# STM32L4P5 register map
File version: 1.8
CPU: CM4 r0p1, little endian, MPU, FPU, 4 interrupt priority bits
Registers are 32-bit, read-write, reset 0x0 unless marked. A register's access mark holds for its fields unless they carry their own. Offsets are from the block's base; [hi:lo] are bit positions; {n}, {i} and the like mark numbered series; 'fields as' and 'values as' point back to an identical list.

## RCC — Reset and clock control
Base 0x40021000
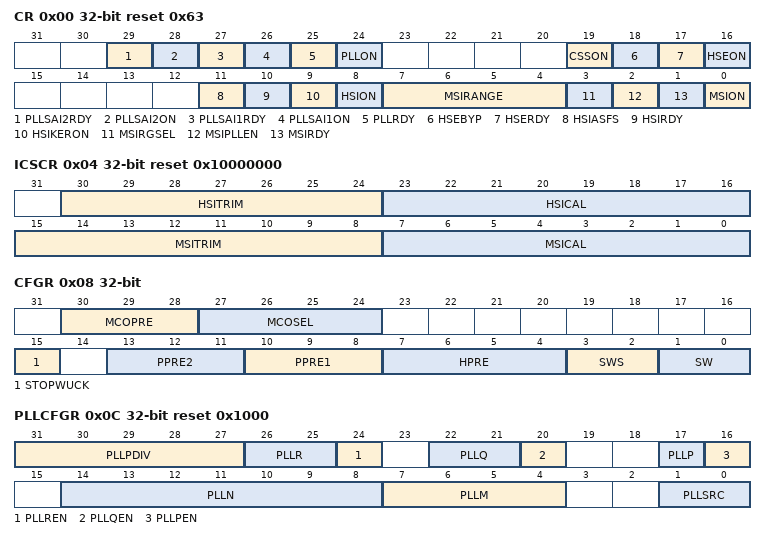
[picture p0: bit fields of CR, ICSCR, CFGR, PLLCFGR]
0x00 CR access per field reset 0x63 — Clock control register
  [29] PLLSAI2RDY ro — SAI2 PLL clock ready flag
    0=Unlocked (PLLSAI2 unlocked); 1=Locked (PLLSAI2 locked)
  [28] PLLSAI2ON rw — SAI2 PLL enable
    0=Disabled (PLLSAI2 OFF); 1=Enabled (PLLSAI2 ON)
  [27] PLLSAI1RDY ro — SAI1 PLL clock ready flag
    0=Unlocked (PLLSAI1 unlocked); 1=Locked (PLLSAI1 locked)
  [26] PLLSAI1ON rw — SAI1 PLL enable
    0=Disabled (PLLSAI1 OFF); 1=Enabled (PLLSAI1 ON)
  [25] PLLRDY ro — Main PLL clock ready flag
    0=Unlocked (PLL unlocked); 1=Locked (PLL locked)
  [24] PLLON rw — Main PLL enable
    0=Disabled (PLL OFF); 1=Enabled (PLL ON)
  [19] CSSON wo — Clock security system enable
    0=Disabled (Clock security system OFF (clock detector OFF)); 1=Enabled (Clock security system ON (Clock detector ON if the HSE oscillator is stable, OFF if not))
  [18] HSEBYP rw — HSE crystal oscillator bypass
    0=NotBypassed (HSE crystal oscillator not bypassed); 1=Bypassed (HSE crystal oscillator bypassed with external clock)
  [17] HSERDY ro — HSE clock ready flag
    0=NotReady (HSE oscillator not ready); 1=Ready (HSE oscillator ready)
  [16] HSEON rw — HSE clock enable
    0=Disabled (HSE oscillator OFF); 1=Enabled (HSE oscillator ON)
  [11] HSIASFS rw — HSI automatic start from Stop
    0=Disabled (HSI16 oscillator is not enabled by hardware when exiting Stop mode with MSI as wakeup clock); 1=Enabled (HSI16 oscillator is enabled by hardware when exiting Stop mode with MSI as wakeup clock)
  [10] HSIRDY ro — HSI clock ready flag
    0=NotReady (HSI16 oscillator not ready); 1=Ready (HSI16 oscillator ready)
  [9] HSIKERON rw — HSI always enable for peripheral kernels
    0=Disabled (No effect on HSI16 oscillator); 1=Enabled (HSI16 oscillator is forced ON even in Stop mode)
  [8] HSION rw — HSI clock enable
    0=Disabled (HSI16 oscillator OFF); 1=Enabled (HSI16 oscillator ON)
  [7:4] MSIRANGE rw — MSI clock ranges
    0=Range100K (range 0 around 100 kHz); 1=Range200K (range 1 around 200 kHz); 2=Range400K (range 2 around 400 kHz); 3=Range800K (range 3 around 800 kHz); 4=Range1M (range 4 around 1 MHz); 5=Range2M (range 5 around 2 MHz); 6=Range4M (range 6 around 4 MHz); 7=Range8M (range 7 around 8 MHz); 8=Range16M (range 8 around 16 MHz); 9=Range24M (range 9 around 24 MHz); 10=Range32M (range 10 around 32 MHz); 11=Range48M (range 11 around 48 MHz)
  [3] MSIRGSEL wo — MSI clock range selection
    0=CSR (MSI Range is provided by MSISRANGE[3:0] in RCC_CSR register); 1=CR (MSI Range is provided by MSIRANGE[3:0] in the RCC_CR register)
  [2] MSIPLLEN rw — MSI clock PLL enable
    0=Disabled (MSI PLL OFF); 1=Enabled (MSI PLL ON)
  [1] MSIRDY ro — MSI clock ready flag
    0=NotReady (MSI oscillator not ready); 1=Ready (MSI oscillator ready)
  [0] MSION rw — MSI clock enable
    0=Disabled (MSI oscillator OFF); 1=Enabled (MSI oscillator ON)
0x04 ICSCR access per field reset 0x10000000 — Internal clock sources calibration register
  [30:24] HSITRIM rw — HSI clock trimming
  [23:16] HSICAL ro — HSI clock calibration
  [15:8] MSITRIM rw — MSI clock trimming
  [7:0] MSICAL ro — MSI clock calibration
0x08 CFGR access per field — Clock configuration register
  [30:28] MCOPRE ro — Microcontroller clock output prescaler
    0=Divider1 (MCO is divided by 1); 1=Divider2 (MCO is divided by 2); 2=Divider4 (MCO is divided by 4); 3=Divider8 (MCO is divided by 8); 4=Divider16 (MCO is divided by 16)
  [27:24] MCOSEL rw — Microcontroller clock output
    0=Disabled (MCO output disabled, no clock on MCO); 1=SYSCLK (SYSCLK system clock selected); 2=MSI (MSI clock selected.); 3=HSI16 (HSI16 clock selected.); 4=HSE (HSE clock selected); 5=Main PLL clock selected; 6=LSI (LSI clock selected); 7=LSE (LSE clock selected); 8=HSI48 (Internal HSI48 clock selected)
  [15] STOPWUCK rw — Wakeup from Stop and CSS backup clock selection
    0=MSI (MSI oscillator selected as wakeup from stop clock and CSS backup clock); 1=HSI16 (HSI16 oscillator selected as wakeup from stop clock and CSS backup clock)
  [13:11] PPRE2 rw — APB high-speed prescaler (APB2)
    4=Div2 (HCLK divided by 2); 5=Div4 (HCLK divided by 4); 6=Div8 (HCLK divided by 8); 7=Div16 (HCLK divided by 16); other=Div1 (HCLK not divided)
  [10:8] PPRE1 rw — PB low-speed prescaler (APB1)
    values as PPRE2
  [7:4] HPRE rw — AHB prescaler
    8=Div2 (SYSCLK divided by 2); 9=Div4 (SYSCLK divided by 4); 10=Div8 (SYSCLK divided by 8); 11=Div16 (SYSCLK divided by 16); 12=Div64 (SYSCLK divided by 64); 13=Div128 (SYSCLK divided by 128); 14=Div256 (SYSCLK divided by 256); 15=Div512 (SYSCLK divided by 512); other=Div1 (SYSCLK not divided)
  [3:2] SWS ro — System clock switch status
    0=MSI (MSI oscillator used as system clock); 1=HSI16 (HSI16 oscillator used as system clock); 2=HSE (HSE used as system clock); 3=PLL (PLL used as system clock)
  [1:0] SW rw — System clock switch
    0=MSI (MSI selected as system clock); 1=HSI16 (HSI16 selected as system clock); 2=HSE (HSE selected as system clock); 3=PLL (PLL selected as system clock)
0x0C PLLCFGR reset 0x1000 — PLL configuration register
  [31:27] PLLPDIV — Main PLL division factor for PLLSAI2CLK
    0=PLLP (PLLSAI3CLK is controlled by the bit PLLP); {v}=Div{v} (PLLSAI3CLK = VCO / {v}) (v=2..31)
  [26:25] PLLR — Main PLL division factor for PLLCLK (system clock)
    0=Div2 (PLLx = 2); 1=Div4 (PLLx = 4); 2=Div6 (PLLx = 6); 3=Div8 (PLLx = 8)
  [24] PLLREN — Main PLL PLLCLK output enable
    0=Disabled (PLLCLK output disable); 1=Enabled (PLLCLK output enabled)
  [22:21] PLLQ — Main PLL division factor for PLLUSB1CLK(48 MHz clock)
    values as PLLR
  [20] PLLQEN — Main PLL PLLUSB1CLK output enable
    0=Disabled (PLL48M1CLK output disable); 1=Enabled (PLL48M1CLK output enabled)
  [17] PLLP — Main PLL division factor for PLLSAI3CLK (SAI1 and SAI2 clock)
    0=Div7 (PLLP = 7); 1=Div17 (PLLP = 17)
  [16] PLLPEN — Main PLL PLLSAI3CLK output enable
    0=Disabled (PLLSAI3CLK output disable); 1=Enabled (PLLSAI3CLK output enabled)
  [14:8] PLLN range 8..127 — Main PLL multiplication factor for VCO
  [7:4] PLLM — Division factor for the main PLL and audio PLL (PLLSAI1 and PLLSAI2) input clock
    {v}=Div{v+1} (PLLM = {v+1}) (v=0..8); 9=Div10 (PLLM = 11); 10=Div11 (PLLM = 12); 11=Div12 (PLLM = 13); {v}=Div{v+1} (PLLM = {v+1}) (v=12..15)
  [1:0] PLLSRC — Main PLL, PLLSAI1 and PLLSAI2 entry clock source
    0=No clock sent to PLL; 1=MSI (MSI clock selected as PLL clock entry); 2=HSI16 (HSI16 clock selected as PLL clock entry); 3=HSE (HSE clock selected as PLL clock entry)
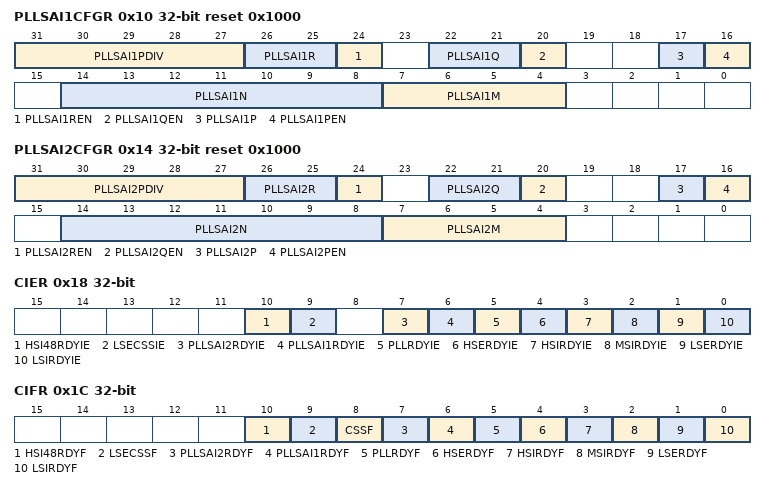
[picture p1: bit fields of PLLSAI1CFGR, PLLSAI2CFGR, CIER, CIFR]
0x10 PLLSAI1CFGR reset 0x1000 — PLLSAI1 configuration register
  [31:27] PLLSAI1PDIV — PLLSAI1 division factor for PLLSAI1CLK
    0=PLLSAI1P (PLLSAI1CLK is controlled by the bit PLLSAI1P); {v}=Div{v} (PLLSAI1CLK = VCOSAI / {v}) (v=2..31)
  [26:25] PLLSAI1R — PLLSAI1 division factor for PLLADC1CLK (ADC clock)
    0=Div2 (PLLSAI1x = 2); 1=Div4 (PLLSAI1x = 4); 2=Div6 (PLLSAI1x = 6); 3=Div8 (PLLSAI1x = 8)
  [24] PLLSAI1REN — PLLSAI1 PLLADC1CLK output enable
    0=Disabled (PLLADC1CLK output disable); 1=Enabled (PLLADC1CLK output enabled)
  [22:21] PLLSAI1Q — SAI1PLL division factor for PLLUSB2CLK (48 MHz clock)
    values as PLLSAI1R
  [20] PLLSAI1QEN — SAI1PLL PLLUSB2CLK output enable
    0=Disabled (PLL48M2CLK output disable); 1=Enabled (PLL48M2CLK output enabled)
  [17] PLLSAI1P — SAI1PLL division factor for PLLSAI1CLK (SAI1 or SAI2 clock)
    0=Div7 (PLLSAI1P = 7); 1=Div17 (PLLSAI1P = 17)
  [16] PLLSAI1PEN — SAI1PLL PLLSAI1CLK output enable
    0=Disabled (PLLSAI1CLK output disable); 1=Enabled (PLLSAI1CLK output enabled)
  [14:8] PLLSAI1N range 8..127 — SAI1PLL multiplication factor for VCO
  [7:4] PLLSAI1M — Division factor for PLLSAI1 input clock
    {v}=Div{v+1} (PLLSAI1M = {v+1}) (v=0..8); 9=Div10 (PLLSAI1M = 11); 10=Div11 (PLLSAI1M = 12); 11=Div12 (PLLSAI1M = 13); {v}=Div{v+1} (PLLSAI1M = {v+1}) (v=12..15)
0x14 PLLSAI2CFGR reset 0x1000 — PLLSAI2 configuration register
  [31:27] PLLSAI2PDIV — PLLSAI2 division factor for PLLSAI2CLK
    0=PLLSAI1P (PLLSAI2CLK is controlled by the bit PLLSAI2P); {v}=Div{v} (PLLSAI2CLK = VCOSAI2 / {v}) (v=2..31)
  [26:25] PLLSAI2R — PLLSAI2 division factor for PLLADC2CLK (ADC clock)
    0=Div2 (PLLSAI2x = 2); 1=Div4 (PLLSAI2x = 4); 2=Div6 (PLLSAI2x = 6); 3=Div8 (PLLSAI2x = 8)
  [24] PLLSAI2REN — PLLSAI2 PLLADC2CLK output enable
    0=Disabled (PLLLCDCLK output disable); 1=Enabled (PLLLCDCLK output enabled)
  [22:21] PLLSAI2Q — SAI2PLL PLLSAI2CLK output enable
    values as PLLSAI2R
  [20] PLLSAI2QEN — PLLSAI2 division factor for PLLDISCLK
    0=Disabled (PLLDSICLK output disable); 1=Enabled (PLLDSICLK output enabled)
  [17] PLLSAI2P — SAI1PLL division factor for PLLSAI2CLK (SAI1 or SAI2 clock)
    0=Div7 (PLLSAI2P = 7); 1=Div17 (PLLSAI2P = 17)
  [16] PLLSAI2PEN — SAI2PLL PLLSAI2CLK output enable
    0=Disabled (PLLSAI2CLK output disable); 1=Enabled (PLLSAI2CLK output enabled)
  [14:8] PLLSAI2N range 8..127 — SAI2PLL multiplication factor for VCO
  [7:4] PLLSAI2M — Division factor for PLLSAI2 input clock
    {v}=Div{v+1} (PLLSAI2M = {v+1}) (v=0..8); 9=Div10 (PLLSAI2M = 11); 10=Div11 (PLLSAI2M = 12); 11=Div12 (PLLSAI2M = 13); {v}=Div{v+1} (PLLSAI2M = {v+1}) (v=12..15)
0x18 CIER — Clock interrupt enable register
  [10] HSI48RDYIE — HSI48 ready interrupt enable
    0=Disabled (HSI48 ready interrupt disabled); 1=Enabled (HSI48 ready interrupt enabled)
  [9] LSECSSIE — LSE clock security system interrupt enable
    0=Disabled (Clock security interrupt caused by LSE clock failure disabled); 1=Enabled (Clock security interrupt caused by LSE clock failure enabled)
  [7] PLLSAI2RDYIE — PLLSAI2 ready interrupt enable
    0=Disabled (PLLSAI2 lock interrupt disabled); 1=Enabled (PLLSAI2 lock interrupt enabled)
  [6] PLLSAI1RDYIE — PLLSAI1 ready interrupt enable
    0=Disabled (PLLSAI1 lock interrupt disabled); 1=Enabled (PLLSAI1 lock interrupt enabled)
  [5] PLLRDYIE — PLL ready interrupt enable
    0=Disabled (PLL lock interrupt disabled); 1=Enabled (PLL lock interrupt enabled)
  [4] HSERDYIE — HSE ready interrupt enable
    0=Disabled (HSE ready interrupt disabled); 1=Enabled (HSE ready interrupt enabled)
  [3] HSIRDYIE — HSI ready interrupt enable
    0=Disabled (HSI16 ready interrupt disabled); 1=Enabled (HSI16 ready interrupt enabled)
  [2] MSIRDYIE — MSI ready interrupt enable
    0=Disabled (MSI ready interrupt disabled); 1=Enabled (MSI ready interrupt enabled)
  [1] LSERDYIE — LSE ready interrupt enable
    0=Disabled (LSE ready interrupt disabled); 1=Enabled (LSE ready interrupt enabled)
  [0] LSIRDYIE — LSI ready interrupt enable
    0=Disabled (LSI ready interrupt disabled); 1=Enabled (LSI ready interrupt enabled)
0x1C CIFR ro — Clock interrupt flag register
  [10] HSI48RDYF — HSI48 ready interrupt flag
    0=NoInterrupt (No clock ready interrupt caused by the HSI48 oscillator); 1=Interrupt (Clock ready interrupt caused by the HSI48 oscillator)
  [9] LSECSSF — LSE Clock security system interrupt flag
    0=NoInterrupt (No clock security interrupt caused by LSE clock failure); 1=Interrupt (Clock security interrupt caused by LSE clock failure)
  [8] CSSF — Clock security system interrupt flag
    0=NoInterrupt (No clock security interrupt caused by HSE clock failure); 1=Interrupt (Clock security interrupt caused by HSE clock failure)
  [7] PLLSAI2RDYF — PLLSAI2 ready interrupt flag
    0=NoInterrupt (No clock ready interrupt caused by PLLSAI2 lock); 1=Interrupt (Clock ready interrupt caused by PLLSAI2 lock)
  [6] PLLSAI1RDYF — PLLSAI1 ready interrupt flag
    0=NoInterrupt (No clock ready interrupt caused by PLLSAI1 lock); 1=Interrupt (Clock ready interrupt caused by PLLSAI1 lock)
  [5] PLLRDYF — PLL ready interrupt flag
    0=NoInterrupt (No clock ready interrupt caused by PLL lock); 1=Interrupt (Clock ready interrupt caused by PLL lock)
  [4] HSERDYF — HSE ready interrupt flag
    0=NoInterrupt (No clock ready interrupt caused by the HSE oscillator); 1=Interrupt (Clock ready interrupt caused by the HSE oscillator)
  [3] HSIRDYF — HSI ready interrupt flag
    0=NoInterrupt (No clock ready interrupt caused by the HSI16 oscillator); 1=Interrupt (Clock ready interrupt caused by the HSI16 oscillator)
  [2] MSIRDYF — MSI ready interrupt flag
    0=NoInterrupt (No clock ready interrupt caused by the MSI oscillator); 1=Interrupt (Clock ready interrupt caused by the MSI oscillator)
  [1] LSERDYF — LSE ready interrupt flag
    0=NoInterrupt (No clock ready interrupt caused by the LSE oscillator); 1=Interrupt (Clock ready interrupt caused by the LSE oscillator)
  [0] LSIRDYF — LSI ready interrupt flag
    0=NoInterrupt (No clock ready interrupt caused by the LSI oscillator); 1=Interrupt (Clock ready interrupt caused by the LSI oscillator)
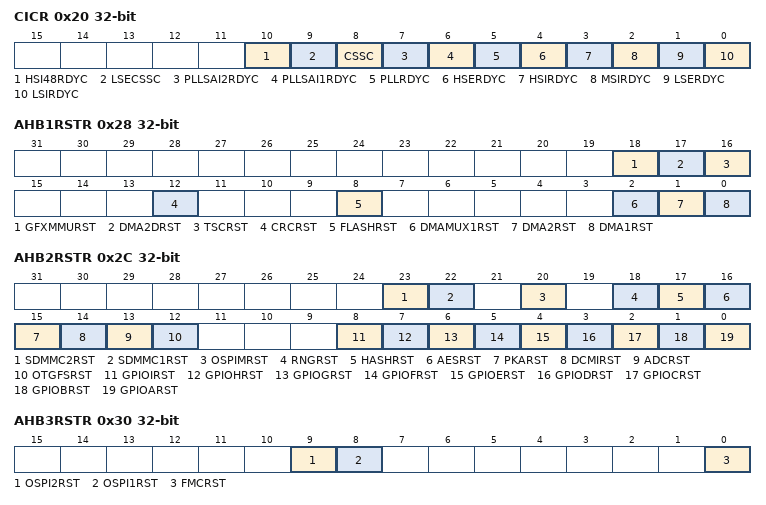
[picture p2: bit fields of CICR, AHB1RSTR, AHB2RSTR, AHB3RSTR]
0x20 CICR wo — Clock interrupt clear register
  [10] HSI48RDYC — HSI48 oscillator ready interrupt clear
    1=Clear the HSI48RDYC flag
  [9] LSECSSC — LSE Clock security system interrupt clear
    1=Clear the LSECSSF flag
  [8] CSSC — Clock security system interrupt clear
    1=Clear the CSSF flag
  [7] PLLSAI2RDYC — PLLSAI2 ready interrupt clear
    1=Clear PLLSAI2RDYF flag
  [6] PLLSAI1RDYC — PLLSAI1 ready interrupt clear
    1=Clear PLLSAI1RDYF flag
  [5] PLLRDYC — PLL ready interrupt clear
    1=Clear PLLRDYF flag
  [4] HSERDYC — HSE ready interrupt clear
    1=Clear HSERDYF flag
  [3] HSIRDYC — HSI ready interrupt clear
    1=Clear HSIRDYF flag
  [2] MSIRDYC — MSI ready interrupt clear
    1=Clear the MSIRDYF flag
  [1] LSERDYC — LSE ready interrupt clear
    1=Clear the LSERDYF flag
  [0] LSIRDYC — LSI ready interrupt clear
    1=Clear the LSIRDYF flag
0x28 AHB1RSTR — AHB1 peripheral reset register
  [18] GFXMMURST — GFXMMU reset
    0=NoEffect; 1=Reset GFXMMU
  [17] DMA2DRST — DMA2D reset
    0=NoEffect; 1=Reset DMA2D
  [16] TSCRST — Touch Sensing Controller reset
    0=NoEffect; 1=Reset TSC
  [12] CRCRST — CRC reset
    0=NoEffect; 1=Reset CRC
  [8] FLASHRST — Flash memory interface reset
    0=NoEffect; 1=Reset Flash memory interface
  [2] DMAMUX1RST — DMAMUXRST
    0=NoEffect; 1=Reset DMAMUX1
  [1] DMA2RST — DMA2 reset
    0=NoEffect; 1=Reset DMA2
  [0] DMA1RST — DMA1 reset
    0=NoEffect; 1=Reset DMA1
0x2C AHB2RSTR — AHB2 peripheral reset register
  [23] SDMMC2RST — SDMMC2 reset
    0=NoEffect; 1=Reset SDMMC2
  [22] SDMMC1RST — SDMMC1 reset
    0=NoEffect; 1=Reset SDMMC1
  [20] OSPIMRST — OCTOSPI IO manager reset
    0=NoEffect; 1=Reset OctoSPI IO manager
  [18] RNGRST — Random number generator reset
    0=NoEffect; 1=Reset RNG
  [17] HASHRST — Hash reset
    0=NoEffect; 1=Reset HASH
  [16] AESRST — AES hardware accelerator reset
    0=NoEffect; 1=Reset AES
  [15] PKARST — PKA reset
    0=NoEffect; 1=Reset PKA
  [14] DCMIRST — Digital Camera Interface reset
    0=NoEffect; 1=Reset DCMI/PSSI interface
  [13] ADCRST — ADC reset
    0=NoEffect; 1=Reset ADC
  [12] OTGFSRST — USB OTG FS reset
    0=NoEffect; 1=Reset USB OTG FS
  [8] GPIOIRST — IO port I reset
    0=NoEffect; 1=Reset GPIO port x
  [7] GPIOHRST — IO port H reset
    0=NoEffect; 1=Reset GPIO port x
  [6] GPIOGRST — IO port G reset
    0=NoEffect; 1=Reset GPIO port x
  [5] GPIOFRST — IO port F reset
    0=NoEffect; 1=Reset GPIO port x
  [4] GPIOERST — IO port E reset
    0=NoEffect; 1=Reset GPIO port x
  [3] GPIODRST — IO port D reset
    0=NoEffect; 1=Reset GPIO port x
  [2] GPIOCRST — IO port C reset
    0=NoEffect; 1=Reset GPIO port x
  [1] GPIOBRST — IO port B reset
    0=NoEffect; 1=Reset GPIO port x
  [0] GPIOARST — IO port A reset
    0=NoEffect; 1=Reset GPIO port x
0x30 AHB3RSTR — AHB3 peripheral reset register
  [9] OSPI2RST — OctOSPI2 memory interface reset
    0=NoEffect; 1=Reset OctoSPIx
  [8] OSPI1RST — OctoSPI1 memory interface reset
    0=NoEffect; 1=Reset OctoSPIx
  [0] FMCRST — Flexible memory controller reset
    0=NoEffect; 1=Reset FMC
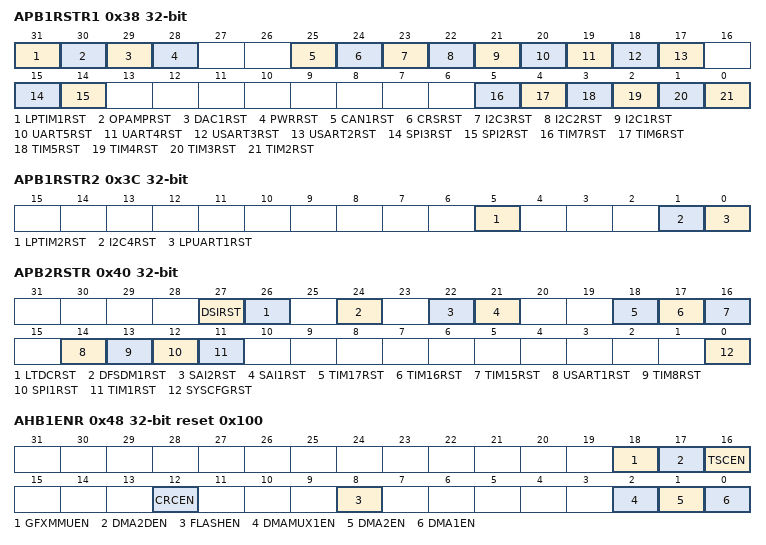
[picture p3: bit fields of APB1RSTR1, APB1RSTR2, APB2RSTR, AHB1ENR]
0x38 APB1RSTR1 — APB1 peripheral reset register 1
  [31] LPTIM1RST — Low Power Timer 1 reset
    0=NoEffect; 1=Reset LPTIM1
  [30] OPAMPRST — OPAMP interface reset
    0=NoEffect; 1=Reset OPAMP
  [29] DAC1RST — DAC1 interface reset
    0=NoEffect; 1=Reset DAC1
  [28] PWRRST — Power interface reset
    0=NoEffect; 1=Reset PWR
  [25] CAN1RST — CAN1 reset
    0=NoEffect; 1=Reset CAN1
  [24] CRSRST — CRS reset
    0=NoEffect; 1=Reset CRS
  [23] I2C3RST — I2C3 reset
    0=NoEffect; 1=Reset I2Cx
  [22] I2C2RST — I2C2 reset
    0=NoEffect; 1=Reset I2Cx
  [21] I2C1RST — I2C1 reset
    0=NoEffect; 1=Reset I2Cx
  [20] UART5RST — UART5 reset
  [19] UART4RST — UART4 reset
  [18] USART3RST — USART3 reset
    0=NoEffect; 1=Reset UARTx
  [17] USART2RST — USART2 reset
    0=NoEffect; 1=Reset UARTx
  [15] SPI3RST — SPI3 reset
    0=NoEffect; 1=Reset SPIx
  [14] SPI2RST — SPI2 reset
    0=NoEffect; 1=Reset SPIx
  [5] TIM7RST — TIM7 timer reset
    0=NoEffect; 1=Reset TIMx
  [4] TIM6RST — TIM6 timer reset
    0=NoEffect; 1=Reset TIMx
  [3] TIM5RST — TIM5 timer reset
    0=NoEffect; 1=Reset TIMx
  [2] TIM4RST — TIM3 timer reset
    0=NoEffect; 1=Reset TIMx
  [1] TIM3RST — TIM3 timer reset
    0=NoEffect; 1=Reset TIMx
  [0] TIM2RST — TIM2 timer reset
    0=NoEffect; 1=Reset TIMx
0x3C APB1RSTR2 — APB1 peripheral reset register 2
  [5] LPTIM2RST — Low-power timer 2 reset
    0=NoEffect; 1=Reset LPTIM2
  [1] I2C4RST — I2C4 reset
    0=NoEffect; 1=Reset I2C4
  [0] LPUART1RST — Low-power UART 1 reset
    0=NoEffect; 1=Reset LPUART1
0x40 APB2RSTR — APB2 peripheral reset register
  [27] DSIRST — DSI reset
    0=NoEffect; 1=Reset DSI
  [26] LTDCRST — LCD-TFT reset
    0=NoEffect; 1=Reset LCD-TFT
  [24] DFSDM1RST — Digital filters for sigma-delata modulators (DFSDM) reset
    0=NoEffect; 1=Reset DFSDM1
  [22] SAI2RST — Serial audio interface 2 (SAI2) reset
    0=NoEffect; 1=Reset SAIx
  [21] SAI1RST — Serial audio interface 1 (SAI1) reset
    0=NoEffect; 1=Reset SAIx
  [18] TIM17RST — TIM17 timer reset
    0=NoEffect; 1=Reset TIMx
  [17] TIM16RST — TIM16 timer reset
    0=NoEffect; 1=Reset TIMx
  [16] TIM15RST — TIM15 timer reset
    0=NoEffect; 1=Reset TIMx
  [14] USART1RST — USART1 reset
    0=NoEffect; 1=Reset UARTx
  [13] TIM8RST — TIM8 timer reset
    0=NoEffect; 1=Reset TIMx
  [12] SPI1RST — SPI1 reset
    0=NoEffect; 1=Reset SPI1
  [11] TIM1RST — TIM1 timer reset
    0=NoEffect; 1=Reset TIMx
  [0] SYSCFGRST — System configuration (SYSCFG) reset
    0=NoEffect; 1=Reset SYSCFG + COMP + VREFBUF
0x48 AHB1ENR reset 0x100 — AHB1 peripheral clock enable register
  [18] GFXMMUEN — Graphic MMU clock enable
    0=Disabled (GFXMMU clock disabled); 1=Enabled (GFXMMU clock enabled)
  [17] DMA2DEN — DMA2D clock enable
    0=Disabled (DMA2D clock disabled); 1=Enabled (DMA2D clock enabled)
  [16] TSCEN — Touch Sensing Controller clock enable
    0=Disabled (TSC clock disabled); 1=Enabled (TSC clock enabled)
  [12] CRCEN — CRC clock enable
    0=Disabled (CRC clock disabled); 1=Enabled (CRC clock enabled)
  [8] FLASHEN — Flash memory interface clock enable
    0=Disabled (Flash memory interface clock disabled); 1=Enabled (Flash memory interface clock enabled)
  [2] DMAMUX1EN — DMAMUX clock enable
    0=Disabled (DMAMUX1 clock disabled); 1=Enabled (DMAMUX1 clock enabled)
  [1] DMA2EN — DMA2 clock enable
    0=Disabled (DMAx clock disabled); 1=Enabled (DMAx clock enabled)
  [0] DMA1EN — DMA1 clock enable
    values as DMA2EN
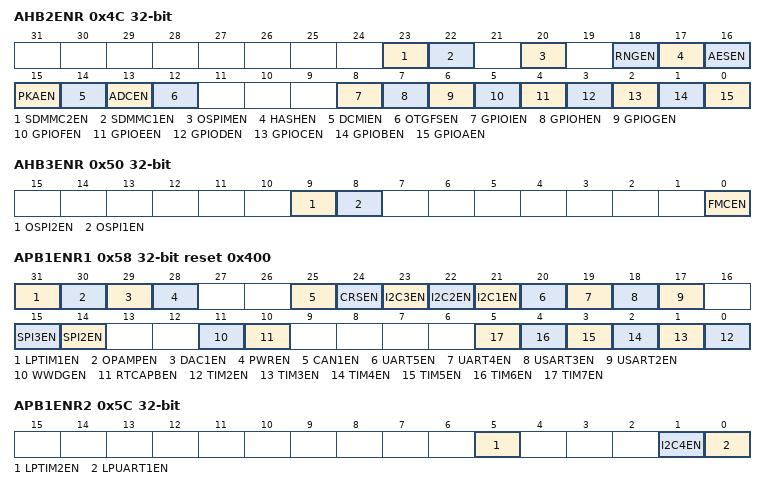
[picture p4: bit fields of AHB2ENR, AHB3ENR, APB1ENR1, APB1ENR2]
0x4C AHB2ENR — AHB2 peripheral clock enable register
  [23] SDMMC2EN — SDMMC2 clock enable
    0=Disabled (SDMMCx clock disabled); 1=Enabled (SDMMCx clock enabled)
  [22] SDMMC1EN — SDMMC1 clock enable
    values as SDMMC2EN
  [20] OSPIMEN — OctoSPI IO manager clock enable
    0=Disabled (OctoSPI IO manager clock disabled); 1=Enabled (OctoSPI IO manager clock enabled)
  [18] RNGEN — Random Number Generator clock enable
    0=Disabled (Random Number Generator clock disabled); 1=Enabled (Random Number Generator clock enabled)
  [17] HASHEN — HASH clock enable
    0=Disabled (HASH clock disabled); 1=Enabled (HASH clock enabled)
  [16] AESEN — AES accelerator clock enable
    0=Disabled (AES clock disabled); 1=Enabled (AES clock enabled)
  [15] PKAEN — PKA clock enable
    0=Disabled (PKA clock disabled); 1=Enabled (PKA clock enabled)
  [14] DCMIEN — DCMI clock enable
    0=Disabled (DCMI/PSSI clock disabled); 1=Enabled (DCMI/PSSI clock enabled)
  [13] ADCEN — ADC clock enable
    0=Disabled (ADC clock disabled); 1=Enabled (ADC clock enabled)
  [12] OTGFSEN — OTG full speed clock enable
    0=Disabled (USB OTG full speed clock disabled); 1=Enabled (USB OTG full speed clock enabled)
  [8] GPIOIEN — IO port I clock enable
    0=Disabled (IO port x clock disabled); 1=Enabled (IO port x clock enabled)
  [7] GPIOHEN — IO port H clock enable
    values as GPIOIEN
  [6] GPIOGEN — IO port G clock enable
    values as GPIOIEN
  [5] GPIOFEN — IO port F clock enable
    values as GPIOIEN
  [4] GPIOEEN — IO port E clock enable
    values as GPIOIEN
  [3] GPIODEN — IO port D clock enable
    values as GPIOIEN
  [2] GPIOCEN — IO port C clock enable
    values as GPIOIEN
  [1] GPIOBEN — IO port B clock enable
    values as GPIOIEN
  [0] GPIOAEN — IO port A clock enable
    values as GPIOIEN
0x50 AHB3ENR — AHB3 peripheral clock enable register
  [9] OSPI2EN — OSPI2EN memory interface clock enable
    0=Disabled (OctoSPI x clock disabled); 1=Enabled (OctoSPI x clock enabled)
  [8] OSPI1EN — OctoSPI1 memory interface clock enable
    values as OSPI2EN
  [0] FMCEN — Flexible memory controller clock enable
    0=Disabled (FMC clock disabled); 1=Enabled (FMC clock enabled)
0x58 APB1ENR1 reset 0x400
  [31] LPTIM1EN — Low power timer 1 clock enable
    0=Disabled (LPTIM1 clock disabled); 1=Enabled (LPTIM1 clock enabled)
  [30] OPAMPEN — OPAMP interface clock enable
    0=Disabled (OPAMP clock disabled); 1=Enabled (OPAMP clock enabled)
  [29] DAC1EN — DAC1 interface clock enable
    0=Disabled (DAC1 clock disabled); 1=Enabled (DAC1 clock enabled)
  [28] PWREN — Power interface clock enable
    0=Disabled (Power interface clock disabled); 1=Enabled (Power interface clock enabled)
  [25] CAN1EN — CAN1 clock enable
    0=Disabled (CAN1 clock disabled); 1=Enabled (CAN1 clock enabled)
  [24] CRSEN — Clock Recovery System clock enable
    0=Disabled (CRS clock disabled); 1=Enabled (CRS clock enabled)
  [23] I2C3EN — I2C3 clock enable
    0=Disabled (I2C3 clock disabled); 1=Enabled (I2C3 clock enabled)
  [22] I2C2EN — I2C2 clock enable
    0=Disabled (I2C2 clock disabled); 1=Enabled (I2C2 clock enabled)
  [21] I2C1EN — I2C1 clock enable
    0=Disabled (I2C1 clock disabled); 1=Enabled (I2C1 clock enabled)
  [20] UART5EN — UART5 clock enable
    0=Disabled (UARTx clock disabled); 1=Enabled (UARTx clock enabled)
  [19] UART4EN — UART4 clock enable
    values as UART5EN
  [18] USART3EN — USART3 clock enable
    0=Disabled (USARTx clock disabled); 1=Enabled (USARTx clock enabled)
  [17] USART2EN — USART2 clock enable
    values as USART3EN
  [15] SPI3EN — SPI3 clock enable
    0=Disabled (SPIx clock disabled); 1=Enabled (SPIx clock enabled)
  [14] SPI2EN — SPI2 clock enable
    values as SPI3EN
  [11] WWDGEN — Window watchdog clock enable
    0=Disabled (Window watchdog clock disabled); 1=Enabled (Window watchdog clock enabled)
  [10] RTCAPBEN — RTC APB clock enable
    0=Disabled (RTC APB clock disabled); 1=Enabled (RTC APB clock enabled)
  [n-2] TIM{n}EN (n=2..7) — TIM{n} timer clock enable
    0=Disabled (TIMx clock disabled); 1=Enabled (TIMx clock enabled)
0x5C APB1ENR2 — APB1 peripheral clock enable register 2
  [5] LPTIM2EN
    0=Disabled (LPTIM2 clock disabled); 1=Enabled (LPTIM2 clock enabled)
  [1] I2C4EN — I2C4 clock enable
    0=Disabled (I2C4 clock disabled); 1=Enabled (I2C4 clock enabled)
  [0] LPUART1EN — Low power UART 1 clock enable
    0=Disabled (LPUART1 clock disabled); 1=Enabled (LPUART1 clock enabled)
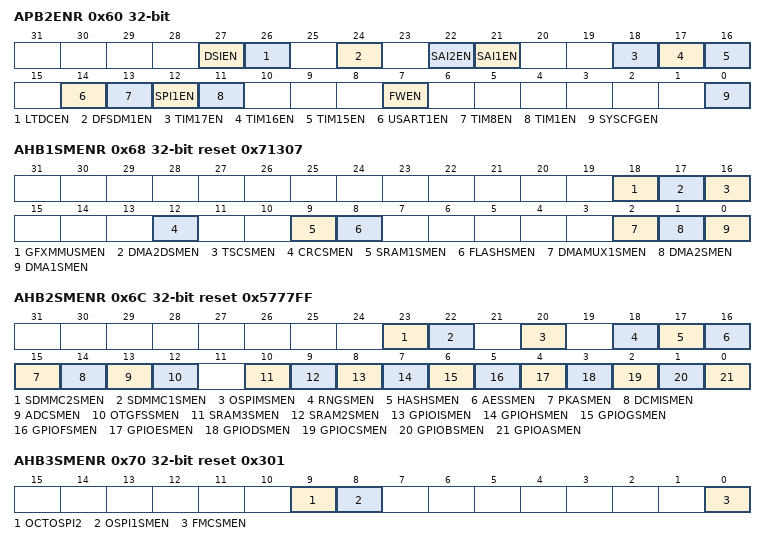
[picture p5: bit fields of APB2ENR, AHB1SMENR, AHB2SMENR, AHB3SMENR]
0x60 APB2ENR
  [27] DSIEN — DSI clock enable
    0=Disabled (DSI clock disabled); 1=Enabled (DSI clock enabled)
  [26] LTDCEN — LCD-TFT clock enable
    0=Disabled (LTDC clock disabled); 1=Enabled (LTDC clock enabled)
  [24] DFSDM1EN — DFSDM timer clock enable
    0=Disabled (DFSDM1 clock disabled); 1=Enabled (DFSDM1 clock enabled)
  [22] SAI2EN — SAI2 clock enable
    0=Disabled (SAIx clock disabled); 1=Enabled (SAIx clock enabled)
  [21] SAI1EN — SAI1 clock enable
    values as SAI2EN
  [18] TIM17EN — TIM17 timer clock enable
    values as APB1ENR1.TIM2EN
  [17] TIM16EN — TIM16 timer clock enable
    values as APB1ENR1.TIM2EN
  [16] TIM15EN — TIM15 timer clock enable
    values as APB1ENR1.TIM2EN
  [14] USART1EN — USART1clock enable
    0=Disabled (USART1 clock disabled); 1=Enabled (USART1 clock enabled)
  [13] TIM8EN — TIM8 timer clock enable
    values as APB1ENR1.TIM2EN
  [12] SPI1EN — SPI1 clock enable
    0=Disabled (SPI1 clock disabled); 1=Enabled (SPI1 clock enabled)
  [11] TIM1EN — TIM1 timer clock enable
    values as APB1ENR1.TIM2EN
  [7] FWEN — Firewall clock enable
    0=Disabled (Firewall clock disabled); 1=Enabled (Firewall clock enabled)
  [0] SYSCFGEN — SYSCFG clock enable
    0=Disabled (SYSCFG + COMP + VREFBUF clock disabled); 1=Enabled (SYSCFG + COMP + VREFBUF clock enabled)
0x68 AHB1SMENR reset 0x71307 — AHB1 peripheral clocks enable in Sleep and Stop modes register
  [18] GFXMMUSMEN — GFXMMU clock enable during Sleep and Stop modes
    0=Disabled (GFXMMU clocks disabled by the clock gating during Sleep and Stop modes); 1=Enabled (GFXMMU clocks enabled by the clock gating(1) during Sleep and Stop modes)
  [17] DMA2DSMEN — DMA2D clock enable during Sleep and Stop modes
    0=Disabled (DMA2D clocks disabled by the clock gating during Sleep and Stop modes); 1=Enabled (DMA2D clocks enabled by the clock gating(1) during Sleep and Stop modes)
  [16] TSCSMEN — Touch Sensing Controller clocks enable during Sleep and Stop modes
    0=Disabled (TSC clocks disabled by the clock gating during Sleep and Stop modes); 1=Enabled (TSC clocks enabled by the clock gating(1) during Sleep and Stop modes)
  [12] CRCSMEN
    0=Disabled (CRC clocks disabled by the clock gating during Sleep and Stop modes); 1=Enabled (CRC clocks enabled by the clock gating(1) during Sleep and Stop modes)
  [9] SRAM1SMEN — SRAM1 interface clocks enable during Sleep and Stop modes
    0=Disabled (SRAM1 clocks disabled by the clock gating during Sleep and Stop modes); 1=Enabled (SRAM1 clocks enabled by the clock gating(1) during Sleep and Stop modes)
  [8] FLASHSMEN — Flash memory interface clocks enable during Sleep and Stop modes
    0=Disabled (Flash memory interface clocks disabled by the clock gating during Sleep and Stop modes); 1=Enabled (Flash memory interface clocks enabled by the clock gating(1) during Sleep and Stop modes)
  [2] DMAMUX1SMEN — DMAMUX clock enable during Sleep and Stop modes
    0=Disabled (DMAMUX1 clocks disabled by the clock gating during Sleep and Stop modes); 1=Enabled (DMAMUX1 clocks enabled by the clock gating(1) during Sleep and Stop modes)
  [1] DMA2SMEN — DMA2 clocks enable during Sleep and Stop modes
    0=Disabled (DMAx clocks disabled by the clock gating during Sleep and Stop modes); 1=Enabled (DMAx clocks enabled by the clock gating(1) during Sleep and Stop modes)
  [0] DMA1SMEN — DMA1 clocks enable during Sleep and Stop modes
    values as DMA2SMEN
0x6C AHB2SMENR reset 0x5777FF — AHB2 peripheral clocks enable in Sleep and Stop modes register
  [23] SDMMC2SMEN — SDMMC2 clocks enable during Sleep and Stop modes
    0=Disabled (SDMMCx clocks disabled by the clock gating during Sleep and Stop modes); 1=Enabled (SDMMCx clocks enabled by the clock gating(1) during Sleep and Stop modes)
  [22] SDMMC1SMEN — SDMMC1 clocks enable during Sleep and Stop modes
    values as SDMMC2SMEN
  [20] OSPIMSMEN — OctoSPI IO manager clocks enable during Sleep and Stop modes
    0=Disabled (OCTOSPIM clocks disabled by the clock gating during Sleep and Stop modes); 1=Enabled (OCTOSPIM clocks enabled by the clock gating(1) during Sleep and Stop modes)
  [18] RNGSMEN — Random Number Generator clocks enable during Sleep and Stop modes
    0=Disabled (Random Number Generator clocks disabled by the clock gating during Sleep and Stop modes); 1=Enabled (Random Number Generator clocks enabled by the clock gating(1) during Sleep and Stop modes)
  [17] HASHSMEN — HASH clock enable during Sleep and Stop modes
    0=Disabled (HASH clocks disabled by the clock gating during Sleep and Stop modes); 1=Enabled (HASH clocks enabled by the clock gating(1) during Sleep and Stop modes)
  [16] AESSMEN — AES accelerator clocks enable during Sleep and Stop modes
    0=Disabled (AES clocks disabled by the clock gating during Sleep and Stop modes); 1=Enabled (AES clocks enabled by the clock gating(1) during Sleep and Stop modes)
  [15] PKASMEN — PKA clocks enable during Sleep and Stop modes
    0=Disabled (PKA clocks disabled by the clock gating during Sleep and Stop modes); 1=Enabled (PKA clocks enabled by the clock gating(1) during Sleep and Stop modes)
  [14] DCMISMEN — DCMI clock enable during Sleep and Stop modes
    0=Disabled (DCMI/PSSI clocks disabled by the clock gating during Sleep and Stop modes); 1=Enabled (DCMI/PSSI clocks enabled by the clock gating(1) during Sleep and Stop modes)
  [13] ADCSMEN — ADC clocks enable during Sleep and Stop modes
    0=Disabled (ADC clocks disabled by the clock gating during Sleep and Stop modes); 1=Enabled (ADC clocks enabled by the clock gating(1) during Sleep and Stop modes)
  [12] OTGFSSMEN — OTG full speed clocks enable during Sleep and Stop modes
    0=Disabled (USB OTG full speed clocks disabled by the clock gating during Sleep and Stop modes); 1=Enabled (USB OTG full speed clocks enabled by the clock gating(1) during Sleep and Stop modes)
  [10] SRAM3SMEN — SRAM2 interface clocks enable during Sleep and Stop modes
    0=Disabled (SRAMx clocks disabled by the clock gating during Sleep and Stop modes); 1=Enabled (SRAMx clocks enabled by the clock gating(1) during Sleep and Stop modes)
  [9] SRAM2SMEN — SRAM2 interface clocks enable during Sleep and Stop modes
    values as SRAM3SMEN
  [8] GPIOISMEN — IO port I clocks enable during Sleep and Stop modes
    0=Disabled (IO port x clocks disabled by the clock gating during Sleep and Stop modes); 1=Enabled (IO port x clocks enabled by the clock gating(1) during Sleep and Stop modes)
  [7] GPIOHSMEN — IO port H clocks enable during Sleep and Stop modes
    values as GPIOISMEN
  [6] GPIOGSMEN — IO port G clocks enable during Sleep and Stop modes
    values as GPIOISMEN
  [5] GPIOFSMEN — IO port F clocks enable during Sleep and Stop modes
    values as GPIOISMEN
  [4] GPIOESMEN — IO port E clocks enable during Sleep and Stop modes
    values as GPIOISMEN
  [3] GPIODSMEN — IO port D clocks enable during Sleep and Stop modes
    values as GPIOISMEN
  [2] GPIOCSMEN — IO port C clocks enable during Sleep and Stop modes
    values as GPIOISMEN
  [1] GPIOBSMEN — IO port B clocks enable during Sleep and Stop modes
    values as GPIOISMEN
  [0] GPIOASMEN — IO port A clocks enable during Sleep and Stop modes
    values as GPIOISMEN
0x70 AHB3SMENR reset 0x301 — AHB3 peripheral clocks enable in Sleep and Stop modes register
  [9] OCTOSPI2 — OctoSPI2 memory interface clocks enable during Sleep and Stop modes
    0=Disabled (OctoSPI2 clocks disabled by the clock gating during Sleep and Stop modes); 1=Enabled (OctoSPI2 clocks enabled by the clock gating(1) during Sleep and Stop modes)
  [8] OSPI1SMEN — OctoSPI1 memory interface clocks enable during Sleep and Stop modes
    0=Disabled (OctoSPI1 clocks disabled by the clock gating during Sleep and Stop modes); 1=Enabled (OctoSPI1 clocks enabled by the clock gating(1) during Sleep and Stop modes)
  [0] FMCSMEN — Flexible memory controller clocks enable during Sleep and Stop modes
    0=Disabled (FMC clocks disabled by the clock gating during Sleep and Stop modes); 1=Enabled (FMC clocks enabled by the clock gating(1) during Sleep and Stop modes)
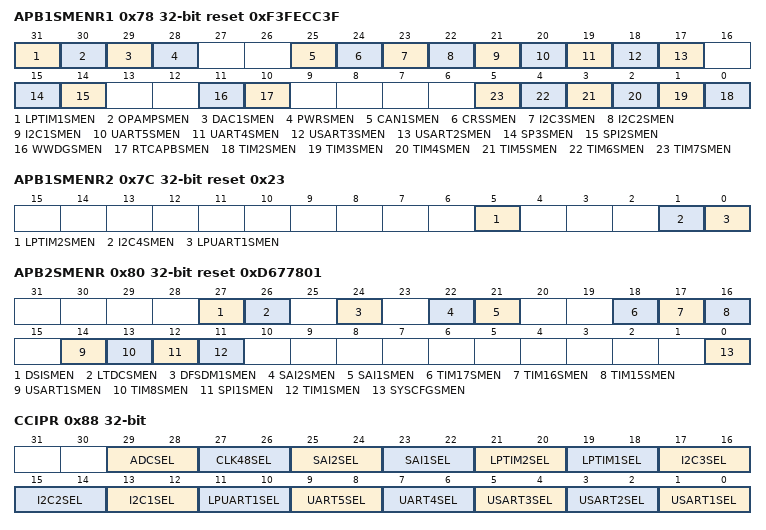
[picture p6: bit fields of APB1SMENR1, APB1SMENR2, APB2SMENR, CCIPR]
0x78 APB1SMENR1 reset 0xF3FECC3F
  [31] LPTIM1SMEN — Low power timer 1 clocks enable during Sleep and Stop modes
    0=Disabled (LPTIM1 clocks disabled by the clock gating during Sleep and Stop modes); 1=Enabled (LPTIM1 clocks enabled by the clock gating(1) during Sleep and Stop modes)
  [30] OPAMPSMEN — OPAMP interface clocks enable during Sleep and Stop modes
    0=Disabled (OPAMP interface clocks disabled by the clock gating during Sleep and Stop modes); 1=Enabled (OPAMP interface clocks enabled by the clock gating(1) during Sleep and Stop modes)
  [29] DAC1SMEN — DAC1 interface clocks enable during Sleep and Stop modes
    0=Disabled (DAC1 interface clocks disabled by the clock gating during Sleep and Stop modes); 1=Enabled (DAC1 interface clocks enabled by the clock gating(1) during Sleep and Stop modes)
  [28] PWRSMEN — Power interface clocks enable during Sleep and Stop modes
    0=Disabled (Power interface clocks disabled by the clock gating during Sleep and Stop modes); 1=Enabled (Power interface clocks enabled by the clock gating(1) during Sleep and Stop modes)
  [25] CAN1SMEN — CAN1 clocks enable during Sleep and Stop modes
    0=Disabled (CAN1 clocks disabled by the clock gating during Sleep and Stop modes); 1=Enabled (CAN1 clocks enabled by the clock gating(1) during Sleep and Stop modes)
  [24] CRSSMEN — CRS clock enable during Sleep and Stop modes
    0=Disabled (CRS clocks disabled by the clock gating during Sleep and Stop modes); 1=Enabled (CRS clocks enabled by the clock gating(1) during Sleep and Stop modes)
  [23] I2C3SMEN — I2C3 clocks enable during Sleep and Stop modes
    0=Disabled (I2Cx clocks disabled by the clock gating during Sleep and Stop modes); 1=Enabled (I2Cx clocks enabled by the clock gating(1) during Sleep and Stop modes)
  [22] I2C2SMEN — I2C2 clocks enable during Sleep and Stop modes
    values as I2C3SMEN
  [21] I2C1SMEN — I2C1 clocks enable during Sleep and Stop modes
    values as I2C3SMEN
  [20] UART5SMEN — UART5 clocks enable during Sleep and Stop modes
    0=Disabled (UARTx clocks disabled by the clock gating during Sleep and Stop modes); 1=Enabled (UARTx clocks enabled by the clock gating(1) during Sleep and Stop modes)
  [19] UART4SMEN — UART4 clocks enable during Sleep and Stop modes
    values as UART5SMEN
  [18] USART3SMEN — USART3 clocks enable during Sleep and Stop modes
    0=Disabled (USARTx clocks disabled by the clock gating during Sleep and Stop modes); 1=Enabled (USARTx clocks enabled by the clock gating(1) during Sleep and Stop modes)
  [17] USART2SMEN — USART2 clocks enable during Sleep and Stop modes
    values as USART3SMEN
  [15] SP3SMEN — SPI3 clocks enable during Sleep and Stop modes
  [14] SPI2SMEN — SPI2 clocks enable during Sleep and Stop modes
    0=Disabled (SPIx clocks disabled by the clock gating during Sleep and Stop modes); 1=Enabled (SPIx clocks enabled by the clock gating(1) during Sleep and Stop modes)
  [11] WWDGSMEN — Window watchdog clocks enable during Sleep and Stop modes
    0=Disabled (Window watchdog clocks disabled by the clock gating during Sleep and Stop modes); 1=Enabled (Window watchdog clocks enabled by the clock gating(1) during Sleep and Stop modes)
  [10] RTCAPBSMEN — RTC APB clock enable during Sleep and Stop modes
    0=Disabled (RTC APB clocks disabled by the clock gating during Sleep and Stop modes); 1=Enabled (RTC APB clocks enabled by the clock gating(1) during Sleep and Stop modes)
  [n-2] TIM{n}SMEN (n=2..7) — TIM{n} timer clocks enable during Sleep and Stop modes
    0=Disabled (TIMx clocks disabled by the clock gating during Sleep and Stop modes); 1=Enabled (TIMx clocks enabled by the clock gating(1) during Sleep and Stop modes)
0x7C APB1SMENR2 reset 0x23 — APB1 peripheral clocks enable in Sleep and Stop modes register 2
  [5] LPTIM2SMEN
    0=Disabled (LPTIM2 clocks disabled by the clock gating during Sleep and Stop modes); 1=Enabled (LPTIM2 clocks enabled by the clock gating(1) during Sleep and Stop modes)
  [1] I2C4SMEN — I2C4 clocks enable during Sleep and Stop modes
    0=Disabled (I2C4 clocks disabled by the clock gating during Sleep and Stop modes); 1=Enabled (I2C4 clocks enabled by the clock gating(1) during Sleep and Stop modes)
  [0] LPUART1SMEN — Low power UART 1 clocks enable during Sleep and Stop modes
    0=Disabled (LPUART1 clocks disabled by the clock gating during Sleep and Stop modes); 1=Enabled (LPUART1 clocks enabled by the clock gating(1) during Sleep and Stop modes)
0x80 APB2SMENR reset 0xD677801
  [27] DSISMEN — DSI clocks enable during Sleep and Stop modes
    0=Disabled (DSI clocks disabled by the clock gating during Sleep and Stop modes); 1=Enabled (DSI clocks enabled by the clock gating(1) during Sleep and Stop modes)
  [26] LTDCSMEN — LCD-TFT timer clocks enable during Sleep and Stop modes
    0=Disabled (LCD-TFT clocks disabled by the clock gating during Sleep and Stop modes); 1=Enabled (LCD-TFT clocks enabled by the clock gating(1) during Sleep and Stop modes)
  [24] DFSDM1SMEN — DFSDM timer clocks enable during Sleep and Stop modes
    0=Disabled (DFSDM1 clocks disabled by the clock gating during Sleep and Stop modes); 1=Enabled (DFSDM1 clocks enabled by the clock gating(1) during Sleep and Stop modes)
  [22] SAI2SMEN — SAI2 clocks enable during Sleep and Stop modes
    0=Disabled (SAIx clocks disabled by the clock gating during Sleep and Stop modes); 1=Enabled (SAIx clocks enabled by the clock gating(1) during Sleep and Stop modes)
  [21] SAI1SMEN — SAI1 clocks enable during Sleep and Stop modes
    values as SAI2SMEN
  [18] TIM17SMEN — TIM17 timer clocks enable during Sleep and Stop modes
    values as APB1SMENR1.TIM2SMEN
  [17] TIM16SMEN — TIM16 timer clocks enable during Sleep and Stop modes
    values as APB1SMENR1.TIM2SMEN
  [16] TIM15SMEN — TIM15 timer clocks enable during Sleep and Stop modes
    values as APB1SMENR1.TIM2SMEN
  [14] USART1SMEN — USART1clocks enable during Sleep and Stop modes
    0=Disabled (USART1 clocks disabled by the clock gating during Sleep and Stop modes); 1=Enabled (USART1 clocks enabled by the clock gating(1) during Sleep and Stop modes)
  [13] TIM8SMEN — TIM8 timer clocks enable during Sleep and Stop modes
    values as APB1SMENR1.TIM2SMEN
  [12] SPI1SMEN — SPI1 clocks enable during Sleep and Stop modes
    0=Disabled (SPI1 clocks disabled by the clock gating during Sleep and Stop modes); 1=Enabled (SPI1 clocks enabled by the clock gating(1) during Sleep and Stop modes)
  [11] TIM1SMEN — TIM1 timer clocks enable during Sleep and Stop modes
    values as APB1SMENR1.TIM2SMEN
  [0] SYSCFGSMEN — SYSCFG clocks enable during Sleep and Stop modes
    0=Disabled (SYSCFG + COMP + VREFBUF clocks disabled by the clock gating during Sleep and Stop modes); 1=Enabled (SYSCFG + COMP + VREFBUF clocks enabled by the clock gating(1) during Sleep and Stop modes)
0x88 CCIPR
  [29:28] ADCSEL — ADCs clock source selection
    0=No clock selected; 1=PLLADC1CLK (PLLADC1CLK clock selected); 3=SYSCLK (SYSCLK clock selected)
  [27:26] CLK48SEL — 48 MHz clock source selection
    0=HSI48 (HSI48 clock selected (only for STM32L41x/L42x/L43x/L44x/L45x/L46x/L49x/L4Ax devices, otherwise no clock selected)); 1=PLL48M2CLK (PLL48M2CLK clock selected); 2=PLL48M1CLK (PLL48M1CLK clock selected); 3=MSI (MSI clock selected)
  [25:24] SAI2SEL — SAI2 clock source selection
  [23:22] SAI1SEL — SAI1 clock source selection
  [21:20] LPTIM2SEL — Low power timer 2 clock source selection
    0=PCLK (PCLK clock selected); 1=LSI (LSI clock selected); 2=HSI16 (HSI16 clock selected); 3=LSE (LSE clock selected)
  [19:18] LPTIM1SEL — Low power timer 1 clock source selection
    values as LPTIM2SEL
  [17:16] I2C3SEL — I2C3 clock source selection
    0=PCLK (PCLK clock selected); 1=SYSCLK (SYSCLK clock selected); 2=HSI16 (HSI16 clock selected)
  [15:14] I2C2SEL — I2C2 clock source selection
    values as I2C3SEL
  [13:12] I2C1SEL — I2C1 clock source selection
    values as I2C3SEL
  [11:10] LPUART1SEL — LPUART1 clock source selection
    0=PCLK (PCLK clock selected); 1=SYSCLK (SYSCLK clock selected); 2=HSI16 (HSI16 clock selected); 3=LSE (LSE clock selected)
  [9:8] UART5SEL — UART5 clock source selection
    values as LPUART1SEL
  [7:6] UART4SEL — UART4 clock source selection
    values as LPUART1SEL
  [5:4] USART3SEL — USART3 clock source selection
    values as LPUART1SEL
  [3:2] USART2SEL — USART2 clock source selection
    values as LPUART1SEL
  [1:0] USART1SEL — USART1 clock source selection
    values as LPUART1SEL
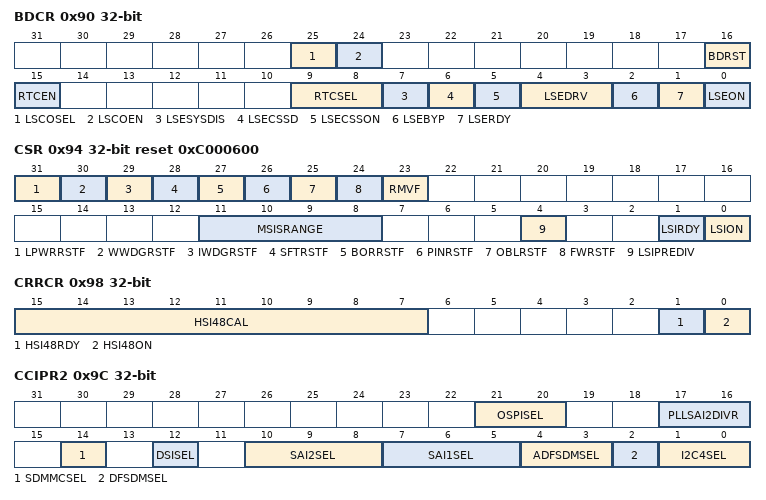
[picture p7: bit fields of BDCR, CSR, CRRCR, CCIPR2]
0x90 BDCR access not given
  [25] LSCOSEL rw — Low speed clock output selection
    0=LSI (LSI clock selected); 1=LSE (LSE clock selected)
  [24] LSCOEN rw — Low speed clock output enable
    0=Disabled (Low speed clock output (LSCO) disabled); 1=Enabled (Low speed clock output (LSCO) enabled)
  [16] BDRST rw — Backup domain software reset
    0=NoReset (Reset not activated); 1=Reset the entire Backup domain
  [15] RTCEN rw — RTC clock enable
    0=Disabled (RTC clock disabled); 1=Enabled (RTC clock enabled)
  [9:8] RTCSEL rw — RTC clock source selection
    0=NoClock; 1=LSE (LSE oscillator clock selected); 2=LSI (LSI oscillator clock selected); 3=HSE (HSE oscillator clock divided by 32 selected)
  [7] LSESYSDIS — Disable the Clock LSE propagation to the system
    0=Disabled (No clock LSE propagation); 1=Enabled (Clock LSE propagation enabled)
  [6] LSECSSD ro
    0=No failure detected on LSE (32 kHz oscillator); 1=Failure detected on LSE (32 kHz oscillator)
  [5] LSECSSON rw
    0=Disabled (CSS on LSE (32 kHz external oscillator) OFF); 1=Enabled (CSS on LSE (32 kHz external oscillator) ON)
  [4:3] LSEDRV rw — SE oscillator drive capability
    0=Low (‘Xtal mode’ lower driving capability); 1=MediumLow (‘Xtal mode’ medium low driving capability); 2=MediumHigh (‘Xtal mode’ medium high driving capability); 3=High (‘Xtal mode’ higher driving capability)
  [2] LSEBYP rw — LSE oscillator bypass
    0=NotBypassed (LSE oscillator not bypassed); 1=Bypassed (LSE oscillator bypassed)
  [1] LSERDY ro — LSE oscillator ready
    0=NotReady (LSE oscillator not ready); 1=Ready (LSE oscillator ready)
  [0] LSEON rw — LSE oscillator enable
    0=Disabled (LSE oscillator OFF); 1=Enabled (LSE oscillator ON)
0x94 CSR access not given reset 0xC000600
  [31] LPWRRSTF ro — Low-power reset flag
    0=NotOccured (No illegal mode reset occurred); 1=Occured (Illegal mode reset occurred)
  [30] WWDGRSTF ro — Window watchdog reset flag
    0=NotOccured (No window watchdog reset occurred); 1=Occured (Window watchdog reset occurred)
  [29] IWDGRSTF ro — Independent window watchdog reset flag
    0=NotOccured (No independent watchdog reset occurred); 1=Occured (Independent watchdog reset occurred)
  [28] SFTRSTF ro — Software reset flag
    0=NotOccured (No software reset occurred); 1=Occured (Software reset occurred)
  [27] BORRSTF ro — BOR flag
    0=NotOccured (No BOR occurred); 1=Occured (BOR occurred)
  [26] PINRSTF ro — Pin reset flag
    0=NotOccured (No reset from NRST pin occurred); 1=Occured (Reset from NRST pin occurred)
  [25] OBLRSTF ro — Option byte loader reset flag
    0=NotOccured (No reset from Option Byte loading occurred); 1=Occured (Reset from Option Byte loading occurred)
  [24] FWRSTF ro — Firewall reset flag
    0=NotOccured (No reset from the firewall occurred); 1=Occured (Reset from the firewall occurred)
  [23] RMVF rw — Remove reset flag
    0=NoEffect; 1=Clear the reset flags
  [11:8] MSISRANGE rw — SI range after Standby mode
    4=Range1M (range 4 around 1 MHz); 5=Range2M (range 5 around 2 MHz); 6=Range4M (range 6 around 4 MHz); 7=Range8M (range 7 around 8 MHz)
  [4] LSIPREDIV — Internal low-speed oscillator predivided by 128
    0=Disabled (LSI PREDIV OFF); 1=Enabled (LSI PREDIV ON)
  [1] LSIRDY ro — LSI oscillator ready
    0=NotReady (LSI oscillator not ready); 1=Ready (LSI oscillator ready)
  [0] LSION rw — LSI oscillator enable
    0=Disabled (LSI oscillator OFF); 1=Enabled (LSI oscillator ON)
0x98 CRRCR access per field — Clock recovery RC register
  [15:7] HSI48CAL ro — HSI48 clock calibration
  [1] HSI48RDY ro — HSI48 clock ready flag
    0=NotReady (HSI48 oscillator not ready); 1=Ready (HSI48 oscillator ready)
  [0] HSI48ON rw — HSI48 clock enable
    0=Disabled (HSI48 oscillator OFF); 1=Enabled (HSI48 oscillator ON)
0x9C CCIPR2 — Peripherals independent clock configuration register
  [21:20] OSPISEL — Octospi clock source selection
    0=SYSCLK (System clock selected as OctoSPI kernel clock); 1=MSI (MSI clock selected as OctoSPI kernel clock); 2=PLL48M1CLK (PLL48M1CLK clock selected as OctoSPI kernel clock)
  [17:16] PLLSAI2DIVR — division factor for LTDC clock
    0=Div2 (PLLSAI2DIVR = /2); 1=Div4 (PLLSAI2DIVR = /4); 2=Div8 (PLLSAI2DIVR = /8); 3=Div16 (PLLSAI2DIVR = /16)
  [14] SDMMCSEL — SDMMC clock selection
    0=HSI48 (48 MHz clock is selected as SDMMC kernel clock); 1=PLLSAI3CLK (PLLSAI3CLK is selected as SDMMC kernel clock, used in case higher frequency than 48MHz is needed (for SDR50 mode))
  [12] DSISEL — clock selection
    0=DSIPHY (DSI-PHY is selected as DSI byte lane clock source (usual case)); 1=PLLDSICLK (PLLDSICLK is selected as DSI byte lane clock source, used in case DSI PLL and DSIPHY are off (low-power mode))
  [10:8] SAI2SEL — SAI2 clock source selection
    0=PLLSAI1CLK (PLLSAI1CLK clock is selected as SAIx clock); 1=PLLSAI2CLK (PLLSAI2CLK clock is selected as SAIx clock); 2=PLLSAI3CLK (PLLSAI3CLK clock is selected as SAIx clock); 3=SAI2_EXTCLK (External clock SAIx_EXTCLK clock selected as SAIx clock); 4=HSI (HSI clock selected as SAIx clock)
  [7:5] SAI1SEL — SAI1 clock source selection
    values as SAI2SEL
  [4:3] ADFSDMSEL — Digital filter for sigma delta modulator audio clock source selection
    0=SAI1 (SAI1clock selected as DFSDM audio clock); 1=HSI (HSI clock selected as DFSDM audio clock); 2=MSI (MSI clock selected as DFSDM audio clock)
  [2] DFSDMSEL — Digital filter for sigma delta modulator kernel clock source selection
    0=PCLK2 (APB2 clock (PCLK2) selected as DFSDM kernel clock); 1=SYSCLK (System clock selected as DFSDM kernel clock)
  [1:0] I2C4SEL — I2C4 clock source selection
    values as CCIPR.I2C3SEL
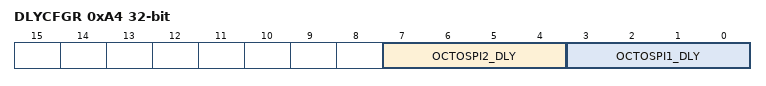
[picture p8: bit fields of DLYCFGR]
0xA4 DLYCFGR access not given — delay configuration register
  [7:4] OCTOSPI2_DLY — Delay sampling configuration on OCTOSPI2 to be used for internal sampling clock (called feedback clock) or for DQS data strobe
  [3:0] OCTOSPI1_DLY — Delay sampling configuration on OCTOSPI1 to be used for internal sampling clock (called feedback clock) or for DQS data strobe
